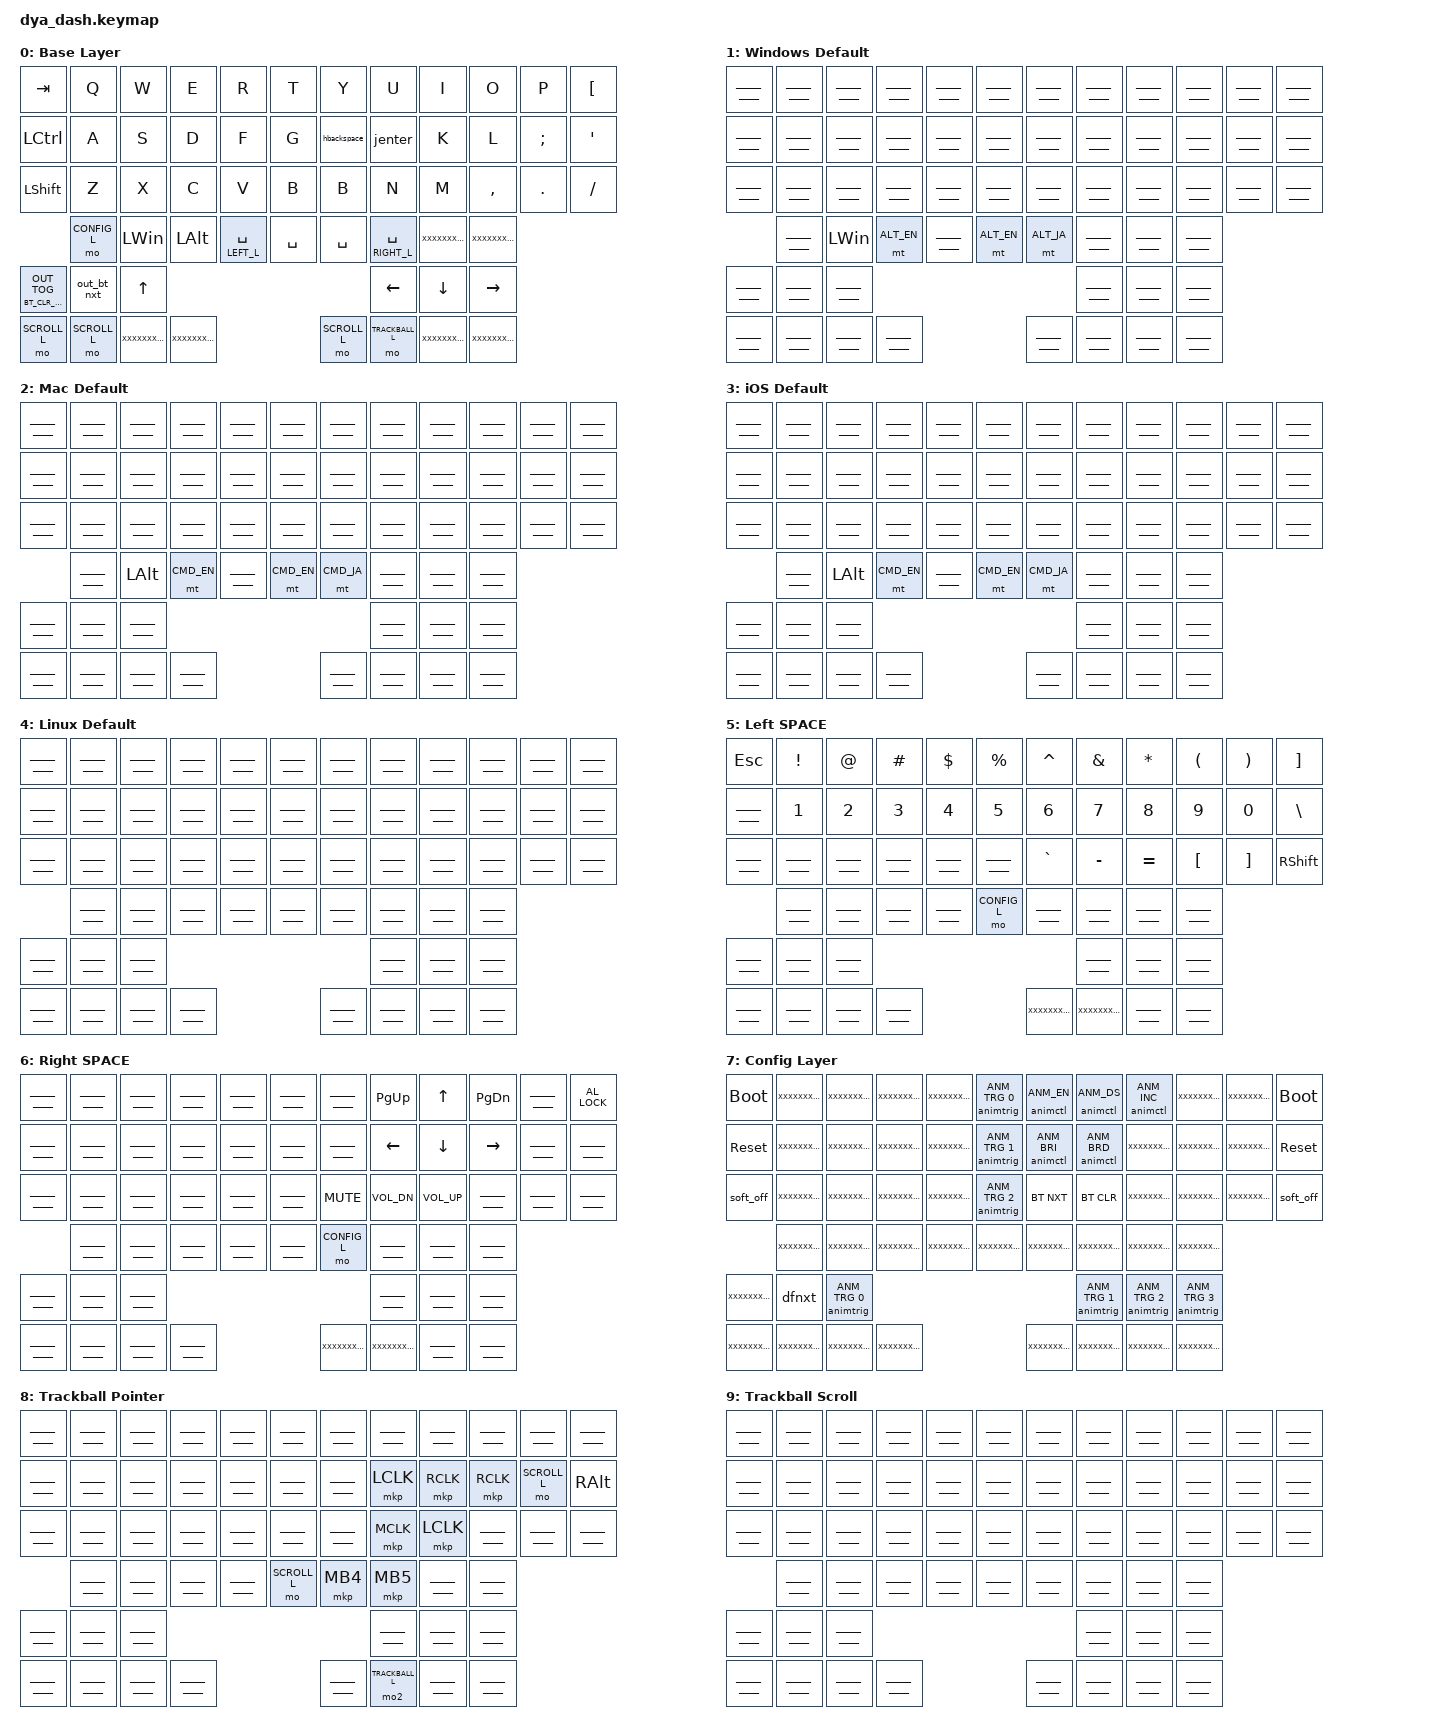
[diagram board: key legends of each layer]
#include <behaviors.dtsi>
#include <behaviors/mouse_move.dtsi>
#include <behaviors/animation_control.dtsi>
#include <behaviors/animation_trigger.dtsi>
#include <dt-bindings/zmk/keys.h>
#include <dt-bindings/zmk/mouse.h>
#include <dt-bindings/zmk/bt.h>
#include <dt-bindings/zmk/outputs.h>
#include <dt-bindings/zmk/rgb.h>
#include <dt-bindings/zmk/ext_power.h>
#include <dt-bindings/zmk_driver_animation/animation_control.h>
#include <dt-bindings/zmk_driver_animation/animation_trigger.h>
#include <dt-bindings/zmk_behavior_default_layer/default_layer.h>
#include "dya_dash_layer.dtsi"

#define CMD_EN LCMD LANG2
#define CMD_JA RCMD LANG1
#define ALT_EN LCMD LANG2
#define ALT_JA RCMD LANG1
#define __________ trans
#define XXXXXXXXXX none

/ {
    behaviors {
        // ctrl+h as backspace
        hbackspace: h_or_ctrl_backspace {
            compatible = "zmk,behavior-mod-morph";
            #binding-cells = <0>;
            bindings = <&kp H>, <&kp BACKSPACE>;
            mods = <(MOD_LCTL)>;
        };
        // ctrl+j as enter
        jenter: j_or_ctrl_enter {
            compatible = "zmk,behavior-mod-morph";
            #binding-cells = <0>;
            bindings = <&kp J>, <&kp ENTER>;
            mods = <(MOD_LCTL)>;
        };
        // output for tap, bt for hold
        outbt: out_bt {
            compatible = "zmk,behavior-hold-tap";
            #binding-cells = <2>;
            flavor = "tap-preferred";
            tapping-term-ms = <1000>;
            bindings = <&bt1param>, <&out>;
            display-name = "Out-BT";
        };

        tog_off: toggle_layer_off_only {
            compatible = "zmk,behavior-toggle-layer";
            #binding-cells = <1>;
            display-name = "Toggle Layer Off";
            toggle-mode = "off";
        };

    };
    macros {
        ZMK_MACRO(out_bt_nxt,
            wait-ms = <50>;
            // Disconnect from all once for reliable connection to selected profile.
            // ZMK automatically reconnects to current profile right after disconnection.
            bindings = <&out OUT_BLE>, <&bt BT_NXT>, <&bt BT_DISC 0>, <&bt BT_DISC 1>, <&bt BT_DISC 2>, <&bt BT_DISC 3>, <&bt BT_DISC 4>;
        )
        ZMK_MACRO(dfnxt,
            bindings = <&df DF_INC>, <&animtrig ANM_TRG 2>;
        )
        // macro to use &bt in hold-tap. two param command is not supported in hold-tap for now.
        bt1param: bt_1param {
            compatible = "zmk,behavior-macro-one-param";
            #binding-cells = <1>;
            wait-ms = <0>;
            bindings = <&macro_param_1to1>, <&bt MACRO_PLACEHOLDER 0>;
        };
        // diactivate speficied layer and execute &mo to disable trackball temp layer disable callback
        mo2: mo2 {
            compatible = "zmk,behavior-macro-one-param";
            #binding-cells = <1>;
            bindings = <&macro_param_1to1>, <&tog_off MACRO_PLACEHOLDER>,
                       <&macro_param_1to1>, <&mo MACRO_PLACEHOLDER>;
        };
    };

    keymap {
        compatible = "zmk,keymap";
        // template {
        //     bindings = <
        //         &__________ &__________ &__________ &__________ &__________ &__________ /**/ &__________ &__________ &__________ &__________ &__________ &__________
        //         &__________ &__________ &__________ &__________ &__________ &__________ /**/ &__________ &__________ &__________ &__________ &__________ &__________
        //         &__________ &__________ &__________ &__________ &__________ &__________ /**/ &__________ &__________ &__________ &__________ &__________ &__________
        //                     &__________ &__________ &__________ &__________ &__________ /**/ &__________ &__________ &__________ &__________
        //
        //         &__________ &__________                                                 /**/ &__________ &__________ &__________ &__________
        //         &__________ &__________ &__________ &__________                         /**/ &__________ &__________ &__________ &__________
        //     >;
        // };
        default_layer {
            display-name = "Base Layer";
            // --------------------------------------------------------------------------------------------------------------------------------------------------
            // |   TAB   |    Q    |    W    |    E       |    R             |    T    |            |    Y    |    U             |    I     |    O    |    P    |    [    |
            // |   CTRL  |    A    |    S    |    D       |    F             |    G    |            |    H    |    J             |    K     |    L    |    ;    |    '    |
            // |  SHIFT  |    Z    |    X    |    C       |    V             |    B    |            |    B    |    N             |    M     |    ,    |    .    |    /    |
            //           |   ALT   |   CMD   |   Cmd (En) |  SPACE or LOWER  |Cmd (En) |            | Cmd(ja) |  Space or LOWER2 |          |         |
            // --------------------------------------------------------------------------------------------------------------------------------------------------
            // | BLE     |  USB    |                                                                |  left   | up   | down | right |
            // | touch1  | touch2  | touch3  | touch 4    |                                         | touch1  | touch2  | touch3  | touch 4 |
            bindings = <
                &kp TAB     &kp Q        &kp W     &kp E      &kp R            &kp T       /**/   &kp Y         &kp U             &kp I       &kp O     &kp P    &kp LBKT
                &kp LCTRL   &kp A        &kp S     &kp D      &kp F            &kp G       /**/   &hbackspace   &jenter           &kp K       &kp L     &kp SEMI &kp SQT
                &kp LSHIFT  &kp Z        &kp X     &kp C      &kp V            &kp B       /**/   &kp B         &kp N             &kp M       &kp COMMA &kp DOT  &kp FSLH
                            &mo CONFIG_L &kp LWIN  &kp LALT   &lt LEFT_L SPACE &kp SPACE   /**/   &kp SPACE     &lt RIGHT_L SPACE &XXXXXXXXXX &XXXXXXXXXX
                &outbt BT_CLR_CMD OUT_TOG &out_bt_nxt                                      /**/   &kp UP        &kp LEFT          &kp DOWN    &kp RIGHT
                &mo SCROLL_L &mo SCROLL_L &XXXXXXXXXX &XXXXXXXXXX                            /**/   &mo SCROLL_L  &mo TRACKBALL_L   &XXXXXXXXXX &XXXXXXXXXX
            >;
        };
        windows_default_layer {
            display-name = "Windows Default";
            bindings = <
                &__________ &__________ &__________ &__________ &__________ &__________ /**/ &__________ &__________ &__________ &__________ &__________ &__________
                &__________ &__________ &__________ &__________ &__________ &__________ /**/ &__________ &__________ &__________ &__________ &__________ &__________
                &__________ &__________ &__________ &__________ &__________ &__________ /**/ &__________ &__________ &__________ &__________ &__________ &__________
                            &__________ &kp LWIN    &mt ALT_EN  &__________ &mt ALT_EN  /**/ &mt ALT_JA  &__________ &__________ &__________

                &__________ &__________                                                 /**/ &__________ &__________ &__________ &__________
                &__________ &__________ &__________ &__________                         /**/ &__________ &__________ &__________ &__________
            >;
        };
        mac_default_layer {
            display-name = "Mac Default";
            bindings = <
                &__________ &__________ &__________ &__________ &__________ &__________ /**/ &__________ &__________ &__________ &__________ &__________ &__________
                &__________ &__________ &__________ &__________ &__________ &__________ /**/ &__________ &__________ &__________ &__________ &__________ &__________
                &__________ &__________ &__________ &__________ &__________ &__________ /**/ &__________ &__________ &__________ &__________ &__________ &__________
                            &__________ &kp LALT    &mt CMD_EN  &__________ &mt CMD_EN  /**/ &mt CMD_JA  &__________ &__________ &__________

                &__________ &__________                                                 /**/ &__________ &__________ &__________ &__________
                &__________ &__________ &__________ &__________                         /**/ &__________ &__________ &__________ &__________
            >;
        };
        ios_default_layer {
            display-name = "iOS Default";
            bindings = <
                &__________ &__________ &__________ &__________ &__________ &__________ /**/ &__________ &__________ &__________ &__________ &__________ &__________
                &__________ &__________ &__________ &__________ &__________ &__________ /**/ &__________ &__________ &__________ &__________ &__________ &__________
                &__________ &__________ &__________ &__________ &__________ &__________ /**/ &__________ &__________ &__________ &__________ &__________ &__________
                            &__________ &kp LALT    &mt CMD_EN  &__________ &mt CMD_EN  /**/ &mt CMD_JA  &__________ &__________ &__________

                &__________ &__________                                                 /**/ &__________ &__________ &__________ &__________
                &__________ &__________ &__________ &__________                         /**/ &__________ &__________ &__________ &__________
            >;
        };
        linux_default_layer {
            display-name = "Linux Default";
            bindings = <
                &__________ &__________ &__________ &__________ &__________ &__________ /**/ &__________ &__________ &__________ &__________ &__________ &__________
                &__________ &__________ &__________ &__________ &__________ &__________ /**/ &__________ &__________ &__________ &__________ &__________ &__________
                &__________ &__________ &__________ &__________ &__________ &__________ /**/ &__________ &__________ &__________ &__________ &__________ &__________
                            &__________ &__________ &__________ &__________ &__________ /**/ &__________ &__________ &__________ &__________

                &__________ &__________                                                 /**/ &__________ &__________ &__________ &__________
                &__________ &__________ &__________ &__________                         /**/ &__________ &__________ &__________ &__________
            >;
        };
        left_layer {
            display-name = "Left SPACE";
            // --------------------------------------------------------------------------------------------------------------------------------------------------------------------
            // |  ESC    |  !  |  @  |  #       |  $  |  %       |                           |  ^  |  &      |  *      |  (  |  )  |  ]  |
            // |         |  1  |  2  |  3       |  4  |  5       |                           |  6  |  7      |  8      |  9  |  0  |  \  |
            // |         |     |     |          |     |          |                           |  `  |  -      |  =      |  [  |  ]  |SHIFT|
            //           |     |     |          |     |          |                           |     |         |         |     |
            bindings = <
                &kp ESC     &kp EXCL    &kp AT      &kp HASH    &kp DLLR    &kp PRCNT   /**/ &kp CARET   &kp AMPS    &kp ASTRK   &kp LPAR    &kp RPAR    &kp RBKT
                &__________ &kp N1      &kp N2      &kp N3      &kp N4      &kp N5      /**/ &kp N6      &kp N7      &kp N8      &kp N9      &kp N0      &kp BACKSLASH
                &__________ &__________ &__________ &__________ &__________ &__________ /**/ &kp GRAVE   &kp MINUS   &kp EQUAL     &kp LBKT    &kp RBKT  &kp RSHIFT
                            &__________ &__________ &__________ &__________ &mo CONFIG_L/**/  &__________ &__________ &__________ &__________

                &__________ &__________                                                 /**/ &__________ &__________ &__________ &__________
                &__________ &__________ &__________ &__________                         /**/ &XXXXXXXXXX &XXXXXXXXXX &__________ &__________
            >;
        };
        right_layer {
            display-name = "Right SPACE";
            bindings = <
                &__________ &__________ &__________ &__________ &__________ &__________ /**/ &__________ &kp PG_UP    &kp UP       &kp PG_DN   &__________ &kp C_AL_LOCK
                &__________ &__________ &__________ &__________ &__________ &__________ /**/ &__________ &kp LEFT     &kp DOWN     &kp RIGHT   &__________ &__________
                &__________ &__________ &__________ &__________ &__________ &__________ /**/ &kp C_MUTE  &kp C_VOL_DN &kp C_VOL_UP &__________ &__________ &__________
                            &__________ &__________ &__________ &__________ &__________ /**/ &mo CONFIG_L &__________  &__________  &__________

                &__________ &__________                                                 /**/ &__________ &__________  &__________  &__________
                &__________ &__________ &__________ &__________                         /**/ &XXXXXXXXXX &XXXXXXXXXX  &__________  &__________
            >;
        };
        config_layer {
            display-name = "Config Layer";
            bindings = <
                &bootloader &XXXXXXXXXX &XXXXXXXXXX &XXXXXXXXXX &XXXXXXXXXX &animtrig ANM_TRG 0 /*bat*/      /**/ &animctl ANM_EN &animctl ANM_DS &animctl ANM_INC &XXXXXXXXXX &XXXXXXXXXX &bootloader
                &sys_reset  &XXXXXXXXXX &XXXXXXXXXX &XXXXXXXXXX &XXXXXXXXXX &animtrig ANM_TRG 1 /*endpoint*/ /**/ &animctl ANM_BRI &animctl ANM_BRD &XXXXXXXXXX &XXXXXXXXXX &XXXXXXXXXX &sys_reset
                &soft_off   &XXXXXXXXXX &XXXXXXXXXX &XXXXXXXXXX &XXXXXXXXXX &animtrig ANM_TRG 2 /*layer*/    /**/ &bt BT_NXT &bt BT_CLR &XXXXXXXXXX &XXXXXXXXXX &XXXXXXXXXX &soft_off
                            &XXXXXXXXXX &XXXXXXXXXX &XXXXXXXXXX &XXXXXXXXXX &XXXXXXXXXX                      /**/ &XXXXXXXXXX &XXXXXXXXXX &XXXXXXXXXX &XXXXXXXXXX

                &XXXXXXXXXX &dfnxt                                                                           /**/ &animtrig ANM_TRG 0 &animtrig ANM_TRG 1 &animtrig ANM_TRG 2 &animtrig ANM_TRG 3
                &XXXXXXXXXX &XXXXXXXXXX &XXXXXXXXXX &XXXXXXXXXX                                              /**/ &XXXXXXXXXX &XXXXXXXXXX &XXXXXXXXXX &XXXXXXXXXX
            >;
        };
        trackball_layer {
            display-name = "Trackball Pointer";
            bindings = <
                &__________ &__________ &__________ &__________ &__________  &__________ /**/ &__________ &__________ &__________ &__________ &__________  &__________
                &__________ &__________ &__________ &__________ &__________  &__________ /**/ &__________ &mkp LCLK   &mkp RCLK   &mkp RCLK   &mo SCROLL_L &kp RALT
                &__________ &__________ &__________ &__________ &__________  &__________ /**/ &__________ &mkp MCLK   &mkp LCLK   &__________ &__________  &__________
                            &__________ &__________ &__________ &__________  &mo SCROLL_L/**/ &mkp MB4    &mkp MB5    &__________ &__________

                &__________ &__________                                                  /**/ &__________ &__________ &__________ &__________
                &__________ &__________ &__________ &__________                          /**/ &__________ &mo2 TRACKBALL_L &__________ &__________
            >;
        };
        scroll_layer {
            display-name = "Trackball Scroll";
            bindings = <
                &__________ &__________ &__________ &__________ &__________ &__________ /**/ &__________ &__________ &__________ &__________ &__________ &__________
                &__________ &__________ &__________ &__________ &__________ &__________ /**/ &__________ &__________ &__________ &__________ &__________ &__________
                &__________ &__________ &__________ &__________ &__________ &__________ /**/ &__________ &__________ &__________ &__________ &__________ &__________
                            &__________ &__________ &__________ &__________ &__________ /**/ &__________ &__________ &__________ &__________

                &__________ &__________                                                 /**/ &__________ &__________ &__________ &__________
                &__________ &__________ &__________ &__________                         /**/ &__________ &__________ &__________ &__________
            >;
        };
        extra1 {
            status = "reserved";
        };
        extra2 {
            status = "reserved";
        };
        extra3 {
            status = "reserved";
        };
    };
};
